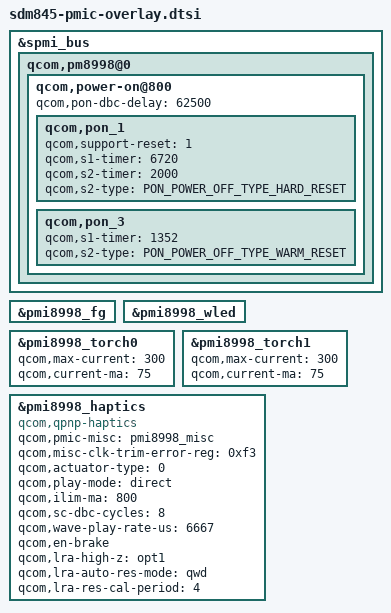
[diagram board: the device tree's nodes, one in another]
&spmi_bus {
    qcom,pm8998@0 {
        qcom,power-on@800 {
            qcom,pon-dbc-delay = <62500>;
            qcom,pon_1 {
                qcom,support-reset = <1>;
                qcom,s1-timer = <6720>;
                qcom,s2-timer = <2000>;
                qcom,s2-type = <PON_POWER_OFF_TYPE_HARD_RESET>;
            };
            qcom,pon_3 {
                qcom,s1-timer = <1352>;
                qcom,s2-type = <PON_POWER_OFF_TYPE_WARM_RESET>;
            };
        };
    };
};

&pmi8998_fg {
    /delete-property/ qcom,hold-soc-while-full;
};

&pmi8998_wled {
    /delete-property/ qcom,auto-calibration;
};

&pmi8998_torch0 {
    qcom,max-current = <300>;
    qcom,current-ma = <75>;
};

&pmi8998_torch1 {
    qcom,max-current = <300>;
    qcom,current-ma = <75>;
};

&pmi8998_haptics {
    compatible = "qcom,qpnp-haptics";
    qcom,pmic-misc = <&pmi8998_misc>;
    qcom,misc-clk-trim-error-reg = <0xf3>;
    qcom,actuator-type = <0>;
    qcom,play-mode = "direct";
    qcom,ilim-ma = <800>;
    qcom,sc-dbc-cycles = <8>;
    qcom,wave-play-rate-us = <6667>;
    qcom,en-brake;
    qcom,lra-high-z = "opt1";
    qcom,lra-auto-res-mode = "qwd";
    qcom,lra-res-cal-period = <4>;
};
